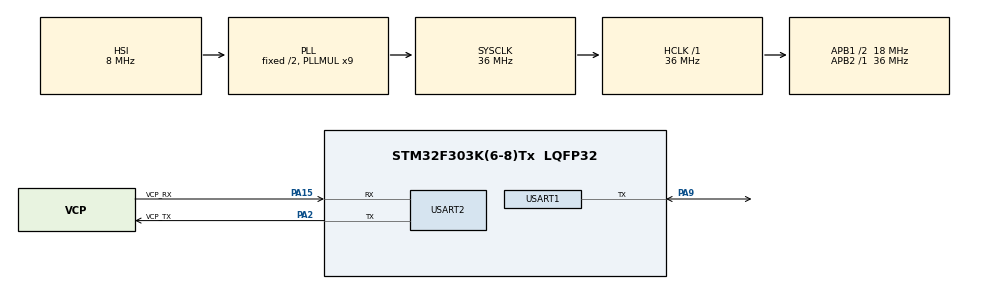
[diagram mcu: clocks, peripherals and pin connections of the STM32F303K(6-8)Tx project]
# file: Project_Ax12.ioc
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Dma.Request0=USART1_RX
Dma.USART1_RX.0.Direction=DMA_PERIPH_TO_MEMORY
Dma.USART1_RX.0.Instance=DMA1_Channel5
Dma.USART1_RX.0.MemDataAlignment=DMA_MDATAALIGN_BYTE
Dma.USART1_RX.0.MemInc=DMA_MINC_ENABLE
Dma.USART1_RX.0.Mode=DMA_CIRCULAR
Dma.USART1_RX.0.PeriphDataAlignment=DMA_PDATAALIGN_BYTE
Dma.USART1_RX.0.PeriphInc=DMA_PINC_DISABLE
Dma.USART1_RX.0.Priority=DMA_PRIORITY_VERY_HIGH
Mcu.Family=STM32F3
Mcu.Name=STM32F303K(6-8)Tx
Mcu.Package=LQFP32
NVIC.DMA1_Channel5_IRQn=true\:0\:0\:false\:false\:true\:false\:true\:true
NVIC.PriorityGroup=NVIC_PRIORITYGROUP_4
NVIC.USART1_IRQn=true\:0\:0\:false\:false\:true\:true\:true\:true
PA13.GPIO_Label=SWDIO
PA13.Mode=Serial_Wire
PA13.Signal=SYS_JTMS-SWDIO
PA14.GPIO_Label=SWCLK
PA14.Mode=Serial_Wire
PA14.Signal=SYS_JTCK-SWCLK
PA15.GPIO_Label=VCP_RX
PA15.Mode=Asynchronous
PA15.Signal=USART2_RX
PA2.GPIO_Label=VCP_TX
PA2.Mode=Asynchronous
PA2.Signal=USART2_TX
PA9.Mode=Half_duplex(single_wire_mode)
PA9.Signal=USART1_TX
PF0\ /\ OSC_IN.GPIO_Label=MCO
PF0\ /\ OSC_IN.Mode=HSE-External-Clock-Source
PF0\ /\ OSC_IN.Signal=RCC_OSC_IN
ProjectManager.HeapSize=0x200
ProjectManager.StackSize=0x400
ProjectManager.TargetToolchain=STM32CubeIDE
RCC.AHBFreq_Value=36000000
RCC.APB1CLKDivider=RCC_HCLK_DIV2
RCC.APB1Freq_Value=18000000
RCC.APB1TimFreq_Value=36000000
RCC.APB2Freq_Value=36000000
RCC.APB2TimFreq_Value=36000000
RCC.CortexFreq_Value=36000000
RCC.HCLKFreq_Value=36000000
RCC.HSE_VALUE=8000000
RCC.HSI_VALUE=8000000
RCC.PLLMUL=RCC_PLL_MUL9
RCC.SYSCLKFreq_VALUE=36000000
RCC.SYSCLKSourceVirtual=RCC_SYSCLKSOURCE_PLLCLK
USART1.BaudRate=250000
USART1.VirtualMode-Half_duplex(single_wire_mode)=VM_ASYNC
USART2.VirtualMode-Asynchronous=VM_ASYNC
board=NUCLEO-F303K8

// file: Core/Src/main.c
/* USER CODE BEGIN Header */
/**
  ******************************************************************************
  * @file           : main.c
  * @brief          : Main program body
  ******************************************************************************
  * @attention
  *
  * Copyright (c) 2023 STMicroelectronics.
  * All rights reserved.
  *
  * This software is licensed under terms that can be found in the LICENSE file
  * in the root directory of this software component.
  * If no LICENSE file comes with this software, it is provided AS-IS.
  *
  ******************************************************************************
  */
/* USER CODE END Header */
#include "main.h"

/* USER CODE BEGIN Includes */
#include "AX12_test.h"
/* USER CODE END Includes */

UART_HandleTypeDef huart1;
UART_HandleTypeDef huart2;
DMA_HandleTypeDef hdma_usart1_rx;

void SystemClock_Config(void);
static void MX_GPIO_Init(void);
static void MX_DMA_Init(void);
static void MX_USART2_UART_Init(void);
static void MX_USART1_UART_Init(void);

int main(void)
{

  /* MCU Configuration--------------------------------------------------------*/

  /* Reset of all peripherals, Initializes the Flash interface and the Systick. */
  HAL_Init();

  /* Configure the system clock */
  SystemClock_Config();

  /* Initialize all configured peripherals */
  MX_GPIO_Init();
  MX_DMA_Init();
  MX_USART2_UART_Init();
  MX_USART1_UART_Init();
  /* USER CODE BEGIN 2 */

  AX12 ax12_1; //( de 60 à 150)
  AX12 ax12_2; //( de 150 à 240)

  /* position ax12 ID_1 */
  int pfermer_1 = 60;
  /* position ax12 ID_2 */
  int pfermer_2 = 240;
  int pouvert = 150;
  int position;

  AX12_Init(&ax12_1, &huart1, 1, BR_250K);
  AX12_setLED(&ax12_1, 1);
  AX12_setMovingSpeed(&ax12_1, 5);
  AX12_setRangeAngle(&ax12_1, 0, 300);
  AX12_setDelayTime(&ax12_1, 180);

  AX12_Init(&ax12_2, &huart1, 2, BR_250K);
  AX12_setLED(&ax12_2, 1);
  AX12_setMovingSpeed(&ax12_2, 5);
  AX12_setRangeAngle(&ax12_2, 0, 300);
  AX12_setDelayTime(&ax12_2, 180);
  /* USER CODE END 2 */

  /* Infinite loop */
  /* USER CODE BEGIN WHILE */
  while (1)
  {
	  AX12_setPosition(&ax12_2,pfermer_2);
	  do
	  {
		  position = AX12_getPosition(&ax12_2);
	  }
	  while(((position > (pfermer_2-pfermer_2*0.05)) && (position < (pfermer_2+pfermer_2*0.05))) == 0);

	  AX12_setPosition(&ax12_1,150);
	  do
	  {
		  position = AX12_getPosition(&ax12_1);
	  }
	  while(((position > (pouvert-pouvert*0.05)) && (position < (pouvert+pouvert*0.05))) == 0);
	  //while((AX12_getPosition(&ax12_1) < (pouvert-pouvert*0.05) ) || (AX12_getPosition(&ax12_1) > (pouvert+pouvert*0.05) )){}

	  AX12_setPosition(&ax12_2, 150);
	  do
	  {
		  position = AX12_getPosition(&ax12_2);
	  }
	  while(((position > (pouvert-pouvert*0.05)) && (position < (pouvert+pouvert*0.05))) == 0);
	  //while((AX12_getPosition(&ax12_2) < (pouvert-pouvert*0.05) ) || (AX12_getPosition(&ax12_2) > (pouvert+pouvert*0.05) )){}

	  AX12_setPosition(&ax12_1,60);
	  do
	  {
		  position = AX12_getPosition(&ax12_1);
	  }
	  while(((position > (pfermer_1-pfermer_1*0.05)) && (position < (pfermer_1+pfermer_1*0.05))) == 0);
	  //while((AX12_getPosition(&ax12_1) < (pfermer_1-pfermer_1*0.05) ) || (AX12_getPosition(&ax12_1) > (pfermer_1+pfermer_1*0.05) )){}

	  //local = AX12_getPosition(&ax12);
	  //AX12_getPosition(&ax12);
	  //AX12_getID(&ax12);
	  //AX12_getPosition(&ax12);
    /* USER CODE END WHILE */

  }
}

void SystemClock_Config(void)
{
  RCC_OscInitTypeDef RCC_OscInitStruct = {0};
  RCC_ClkInitTypeDef RCC_ClkInitStruct = {0};
  RCC_PeriphCLKInitTypeDef PeriphClkInit = {0};

  /** Initializes the RCC Oscillators according to the specified parameters
  * in the RCC_OscInitTypeDef structure.
  */
  RCC_OscInitStruct.OscillatorType = RCC_OSCILLATORTYPE_HSI;
  RCC_OscInitStruct.HSIState = RCC_HSI_ON;
  RCC_OscInitStruct.HSICalibrationValue = RCC_HSICALIBRATION_DEFAULT;
  RCC_OscInitStruct.PLL.PLLState = RCC_PLL_ON;
  RCC_OscInitStruct.PLL.PLLSource = RCC_PLLSOURCE_HSI;
  RCC_OscInitStruct.PLL.PLLMUL = RCC_PLL_MUL9;
  if (HAL_RCC_OscConfig(&RCC_OscInitStruct) != HAL_OK)
  {
    Error_Handler();
  }

  /** Initializes the CPU, AHB and APB buses clocks
  */
  RCC_ClkInitStruct.ClockType = RCC_CLOCKTYPE_HCLK|RCC_CLOCKTYPE_SYSCLK
                              |RCC_CLOCKTYPE_PCLK1|RCC_CLOCKTYPE_PCLK2;
  RCC_ClkInitStruct.SYSCLKSource = RCC_SYSCLKSOURCE_PLLCLK;
  RCC_ClkInitStruct.AHBCLKDivider = RCC_SYSCLK_DIV1;
  RCC_ClkInitStruct.APB1CLKDivider = RCC_HCLK_DIV2;
  RCC_ClkInitStruct.APB2CLKDivider = RCC_HCLK_DIV1;

  if (HAL_RCC_ClockConfig(&RCC_ClkInitStruct, FLASH_LATENCY_1) != HAL_OK)
  {
    Error_Handler();
  }
  PeriphClkInit.PeriphClockSelection = RCC_PERIPHCLK_USART1;
  PeriphClkInit.Usart1ClockSelection = RCC_USART1CLKSOURCE_PCLK1;
  if (HAL_RCCEx_PeriphCLKConfig(&PeriphClkInit) != HAL_OK)
  {
    Error_Handler();
  }
}

static void MX_USART1_UART_Init(void)
{

  huart1.Instance = USART1;
  huart1.Init.BaudRate = 250000;
  huart1.Init.WordLength = UART_WORDLENGTH_8B;
  huart1.Init.StopBits = UART_STOPBITS_1;
  huart1.Init.Parity = UART_PARITY_NONE;
  huart1.Init.Mode = UART_MODE_TX_RX;
  huart1.Init.HwFlowCtl = UART_HWCONTROL_NONE;
  huart1.Init.OverSampling = UART_OVERSAMPLING_16;
  huart1.Init.OneBitSampling = UART_ONE_BIT_SAMPLE_DISABLE;
  huart1.AdvancedInit.AdvFeatureInit = UART_ADVFEATURE_NO_INIT;
  if (HAL_HalfDuplex_Init(&huart1) != HAL_OK)
  {
    Error_Handler();
  }

}

static void MX_USART2_UART_Init(void)
{

  huart2.Instance = USART2;
  huart2.Init.BaudRate = 38400;
  huart2.Init.WordLength = UART_WORDLENGTH_8B;
  huart2.Init.StopBits = UART_STOPBITS_1;
  huart2.Init.Parity = UART_PARITY_NONE;
  huart2.Init.Mode = UART_MODE_TX_RX;
  huart2.Init.HwFlowCtl = UART_HWCONTROL_NONE;
  huart2.Init.OverSampling = UART_OVERSAMPLING_16;
  huart2.Init.OneBitSampling = UART_ONE_BIT_SAMPLE_DISABLE;
  huart2.AdvancedInit.AdvFeatureInit = UART_ADVFEATURE_NO_INIT;
  if (HAL_UART_Init(&huart2) != HAL_OK)
  {
    Error_Handler();
  }

}

static void MX_DMA_Init(void)
{

  /* DMA controller clock enable */
  __HAL_RCC_DMA1_CLK_ENABLE();

  /* DMA interrupt init */
  /* DMA1_Channel5_IRQn interrupt configuration */
  HAL_NVIC_SetPriority(DMA1_Channel5_IRQn, 0, 0);
  HAL_NVIC_EnableIRQ(DMA1_Channel5_IRQn);

}

static void MX_GPIO_Init(void)
{

  /* GPIO Ports Clock Enable */
  __HAL_RCC_GPIOF_CLK_ENABLE();
  __HAL_RCC_GPIOA_CLK_ENABLE();

}

void Error_Handler(void)
{
  __disable_irq();
  while (1)
  {
  }
}
